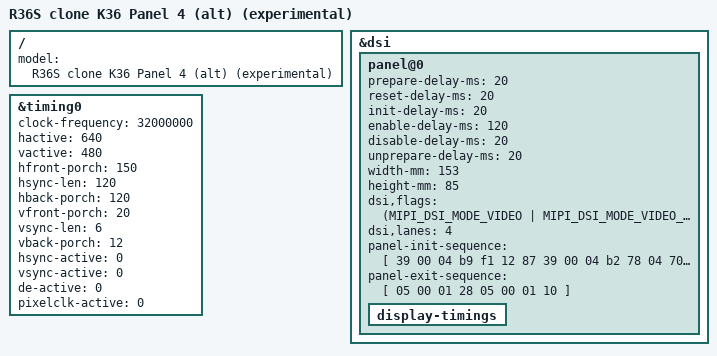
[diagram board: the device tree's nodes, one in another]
// SPDX-License-Identifier: (GPL-2.0+ OR MIT)
/*
 * EXPERIMENTAL - not tested on hardware by andr36oid. Keep a copy of the
 * files you replace so you can go back.
 *
 * EE clone, K36 wiring (same board as EE-K36-Panel1 / EE-K36-Panel4:
 * LCD reset GPIO3_B7, LCD power GPIO0_B5, stick mux enable GPIO2_B4).
 * Panel: arkos4clone "clone type1 panel4". Its init sequence is not the one
 * in rk3326-r36s-clone-k36-panel4.dts, so try this when EE-K36-Panel4
 * gives a wrong picture.
 *
 * Panel values (delays, size, flags, init and exit sequence, timing) are
 * copied from the reference DTB:
 *   lcdyk0517/arkos4clone @2656e5b6, boot/dArkOS/consoles/clone type1 panel4
 *   init sequence 375 bytes, md5 a00bd8c7ed08
 */

/dts-v1/;

#include "rk3326-r36s-clone-ee-k36.dtsi"

/ {
	model = "R36S clone K36 Panel 4 (alt) (experimental)";
};

&dsi {
	panel@0 {
		prepare-delay-ms = <20>;
		reset-delay-ms = <20>;
		init-delay-ms = <20>;
		enable-delay-ms = <120>;
		disable-delay-ms = <20>;
		unprepare-delay-ms = <20>;
		width-mm = <153>;
		height-mm = <85>;
		dsi,flags = <(MIPI_DSI_MODE_VIDEO |
		      MIPI_DSI_MODE_VIDEO_BURST |
		      MIPI_DSI_MODE_EOT_PACKET |
		      MIPI_DSI_MODE_LPM)>;
		dsi,lanes = <4>;
		panel-init-sequence = [
			39 00 04 b9 f1 12 87
			39 00 04 b2 78 04 70
			39 00 0b b3 10 10 fc fc 03 ff 00 00 00 00
			15 00 02 b4 80
			15 00 03 b5 06 06
			15 00 03 b6 a9 a9
			39 00 05 b8 26 22 f0 13
			39 00 1c ba 33 81 05 f9 0e 0e 20 00 00 00 00 00 00 00 44 25 00 91 0a 00 00 01 4f 01 00 00 37
			39 00 02 bc 47
			39 00 06 bf 02 10 00 80 04
			39 00 0a c0 73 73 50 50 00 00 12 73 00
			39 00 12 c1 25 c0 32 32 99 e4 77 77 cc cc ff ff 11 11 00 00 32
			39 00 0d c7 10 00 0a 00 00 00 00 00 ed c5 00 a5
			39 00 05 c8 10 40 1e 03
			39 00 02 cc 0b
			39 00 23 e0 00 0a 0f 29 3c 3f 41 38 08 0c 0f 12 14 12 13 12 19 00 0a 0f 29 3c 3f 41 38 08 0c 0f 12 14 12 13 12 19
			39 00 08 e1 11 11 91 00 00 00 00
			39 00 0f e3 07 07 0b 0b 0b 0b 00 00 00 00 ff 04 c0 10
			39 00 40 e9 c8 10 0a 00 00 f0 81 12 31 23 4f 86 f0 81 47 08 00 00 10 00 00 00 00 00 10 00 00 00 88 88 08 f8 f4 46 60 02 28 88 88 88 88 18 f8 f5 57 71 13 38 88 88 00 00 00 01 00 00 00 00 00 00 00 00 00
			39 00 3e ea 00 1a 00 00 00 00 00 00 00 00 00 00 88 f8 18 f8 83 31 17 75 58 88 88 88 f8 08 f8 82 20 06 64 48 88 88 23 00 00 02 fe 00 00 00 00 00 00 00 00 00 00 00 00 00 00 00 00 00 00 00 00 00 00
			39 00 04 ef ff ff 01
			05 fa 01 11
			05 32 01 29
		];
		panel-exit-sequence = [
			05 00 01 28
			05 00 01 10
		];
		display-timings {
			/* one mode only: the R36S alternates do not fit this panel */
			/delete-node/ timing1;
			/delete-node/ timing2;
		};
	};
};

&timing0 {
	clock-frequency = <32000000>;
	hactive = <640>;
	vactive = <480>;
	hfront-porch = <150>;
	hsync-len = <120>;
	hback-porch = <120>;
	vfront-porch = <20>;	/* stock value, 59.98 Hz */
	vsync-len = <6>;
	vback-porch = <12>;
	hsync-active = <0>;
	vsync-active = <0>;
	de-active = <0>;
	pixelclk-active = <0>;
};
